# HSM_TC3xx register map
Vendor: Infineon; Series: AURIX TC3xx; File version: 2.0
CPU: CM3 r2p0, little endian, MPU, no FPU, 3 interrupt priority bits
Registers are 32-bit, read-write, no defined reset value unless marked. A register's access mark holds for its fields unless they carry their own. Offsets are from the block's base; [hi:lo] are bit positions; {n}, {i} and the like mark numbered series.

## HSM_BRIDGE — HSM bridge, host side (HSM TS 9.3.1, 9.4). Only 32-bit aligned accesses. DBGBASE and HSMOTGB are only accessible while HSM debugging is enabled (DBGCTRL.HSM).
Base 0xF0040000
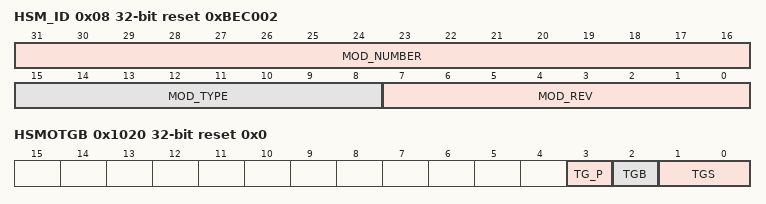
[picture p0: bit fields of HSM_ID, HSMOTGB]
0x08 HSM_ID ro reset 0xBEC002 (reset mask 0xFFFFFF00) — Module Identifier Register (for the whole HSM)
  [31:16] MOD_NUMBER — Module number (00BEH = HSM)
  [15:8] MOD_TYPE — Module type (C0H = 32-bit module)
  [7:0] MOD_REV — Module revision number
0x20 HT2HSMF reset 0x0 write-1-sets — Host to HSM Flag Register. The host sets flags (write 1) to request an HSM interrupt; the HSM resets them.
  [31:0] HT2HSMF — Host to HSM flags
0x28 HSM2HTF reset 0x0 write-1-clears — HSM to Host Flag Register. The HSM sets flags to request a host interrupt; the host resets them (write 1).
  [31:0] HSM2HTF — HSM to host flags
0x2C HSM2HTIE reset 0x0 — HSM to Host Interrupt Enable
  [31:0] HSM2HTIE — Interrupt enable per HSM2HTF flag
0x30 HSM2HTIS reset 0x0 — HSM to Host Interrupt Select
  [31:0] HSM2HTIS — Set: flag mapped to host interrupt 1, otherwise host interrupt 0
0x34 HSM2HTS ro reset 0x0 — HSM to Host Status (written by the HSM; BOS status, HSM TS 11.3)
  [31:0] HSM2HTS — HSM internal status for the host
0x38 HT2HSMS reset 0x0 — Host to HSM Status
  [31:0] HT2HSMS — Host software status for the HSM
0x1000 HSMCTRL reset 0x3 write-1-sets — HSM Control Register (HSM reset / end of memory BIST). Bits can only be set.
  [1:0] EOMBT — End of Memory BIST test (redundant encoding)
    0=MON (MBIST mode activated); 1=MOFF1 (MBIST mode deactivated); 2=MOFF2 (MBIST mode deactivated); 3=MOFF3 (MBIST mode deactivated, start of HSM subsystem)
0x1010 DBGBASE ro reset 0x0 — Debug Base Address Register: upper 16 bits of the HSM address shown in the debug window. Written by the debug server before every window access (read-only here).
  [31:16] BASE — Base address of the debug memory window
0x1020 HSMOTGB reset 0x0 — OCDS Suspend and Trigger Bus Control (cleared by application reset)
  [3] TG_P — TGS, TGB write protection: TGS and TGB are only written if TG_P is set in the same access. Reads as 0.
  [2] TGB — OTGB0/1 bus select
    0=BUS0 (Trigger set on OTGB0); 1=BUS1 (Trigger set on OTGB1)
  [1:0] TGS — Trigger set for OTGB0/1
    0=NOTS (No trigger set output); 1=TS1 (Trigger set 1); 2=TS2 (No trigger set output); 3=TS3 (Trigger set 1)

## HSM_AES — AES-128 module (HSM TS 4.4). Only 32-bit accesses; unused addresses give a bus error. Not suspended in HALT mode.
Base 0xE8000000
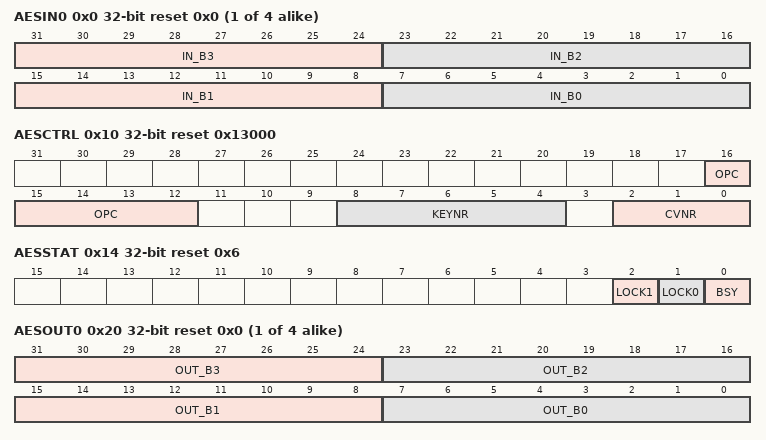
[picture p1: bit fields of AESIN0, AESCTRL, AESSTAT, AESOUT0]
{0x0+4i} AESIN{i} reset 0x0 (i=0..3) — AES input register {i} (key, IV, plain or cipher text)
  [31:24] IN_B3 — Input byte 4n+3
  [23:16] IN_B2 — Input byte 4n+2
  [15:8] IN_B1 — Input byte 4n+1
  [7:0] IN_B0 — Input byte 4n
0x10 AESCTRL reset 0x13000 — AES Control Register (writing triggers the operation)
  [16:12] OPC — Operation code
    0=ECB_ENC (ECB encrypt); 1=ECB_DEC (ECB decrypt); 2=CBC_ENC (CBC encrypt); 3=CBC_DEC (CBC decrypt); 4=CTR (CTR en-/decrypt); 5=OFB (OFB en-/decrypt); 6=CFB_ENC (CFB encrypt); 7=CFB_DEC (CFB decrypt); 8=GCM_ENC (GCM encrypt); 9=GCM_DEC (GCM decrypt); 10=GCM_MAC (G-hash input); 11=XTS_ENC (XTS encrypt); 12=XTS_DEC (XTS decrypt); 16=WK (Write input to key register KEYNR); 17=LK (Lock key register K0 or K1); 18=WCV (Write input to chaining variable CVNR); 19=RCV (Copy chaining variable CVNR to output)
  [8:4] KEYNR — Key number (0-7; 1FH = OLDKEY, key of the last operation)
  [2:0] CVNR — Chaining variable number (0-4)
0x14 AESSTAT ro reset 0x6 — AES Status Register
  [2] LOCK1 — Key K1 locked
    0=K1WENABLED (K1 writable); 1=K1LOCKED
  [1] LOCK0 — Key K0 locked
    0=K0WENABLED (K0 writable); 1=K0LOCKED
  [0] BSY — Busy flag
    0=IDLE; 1=BUSY (Operation running)
{0x20+4i} AESOUT{i} ro reset 0x0 (i=0..3) — AES output register {i}
  [31:24] OUT_B3 — Output byte 4n+3
  [23:16] OUT_B2 — Output byte 4n+2
  [15:8] OUT_B1 — Output byte 4n+1
  [7:0] OUT_B0 — Output byte 4n
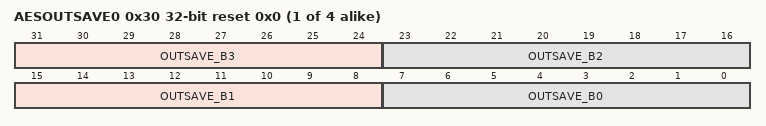
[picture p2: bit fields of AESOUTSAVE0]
{0x30+4i} AESOUTSAVE{i} ro reset 0x0 (i=0..3) — AES output save register {i} (output of the previous operation)
  [31:24] OUTSAVE_B3 — Output byte 4n+3
  [23:16] OUTSAVE_B2 — Output byte 4n+2
  [15:8] OUTSAVE_B1 — Output byte 4n+1
  [7:0] OUTSAVE_B0 — Output byte 4n
